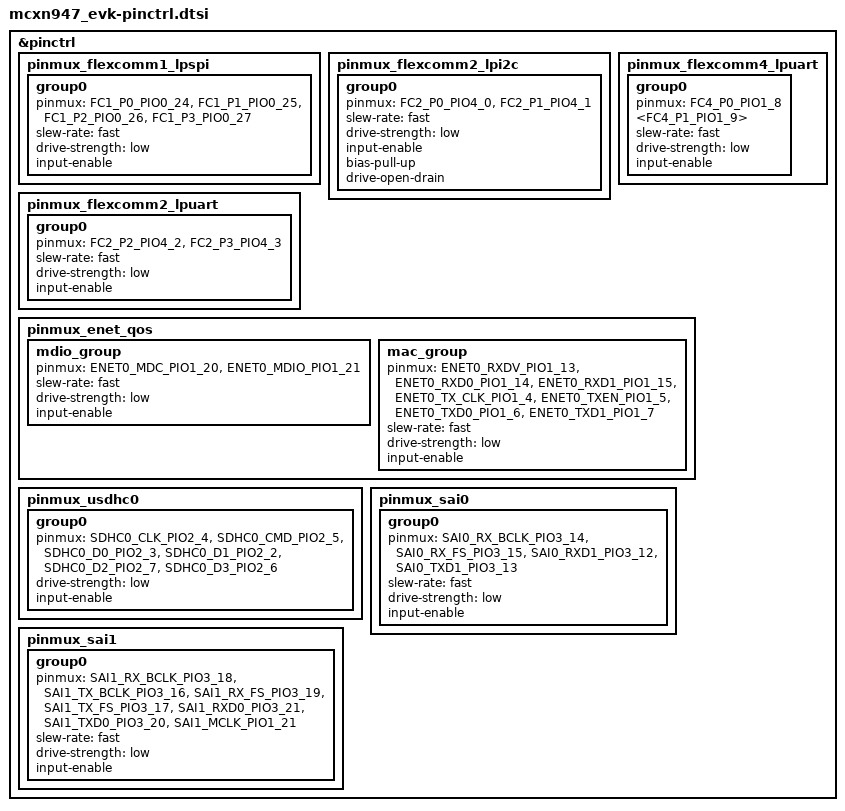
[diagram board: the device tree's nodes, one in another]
/*
 * Copyright 2024 Open Pixel Systems
 * SPDX-License-Identifier: Apache-2.0
 */

#include <nxp/mcx/MCXN947VDF-pinctrl.h>

&pinctrl {
	pinmux_flexcomm1_lpspi: pinmux_flexcomm1_lpspi {
		group0 {
			pinmux = <FC1_P0_PIO0_24>,
				<FC1_P1_PIO0_25>,
				<FC1_P2_PIO0_26>,
				<FC1_P3_PIO0_27>;
			slew-rate = "fast";
			drive-strength = "low";
			input-enable;
		};
	};

	pinmux_flexcomm2_lpi2c: pinmux_flexcomm2_lpi2c {
		group0 {
			pinmux = <FC2_P0_PIO4_0>,
				<FC2_P1_PIO4_1>;
			slew-rate = "fast";
			drive-strength = "low";
			input-enable;
			bias-pull-up;
			drive-open-drain;
		};
	};

	pinmux_flexcomm2_lpuart: pinmux_flexcomm2_lpuart {
		group0 {
			pinmux = <FC2_P2_PIO4_2>,
				<FC2_P3_PIO4_3>;
			slew-rate = "fast";
			drive-strength = "low";
			input-enable;
		};
	};

	pinmux_flexcomm4_lpuart: pinmux_flexcomm4_lpuart {
		group0 {
			pinmux = <FC4_P0_PIO1_8>;
				<FC4_P1_PIO1_9>;
			slew-rate = "fast";
			drive-strength = "low";
			input-enable;
		};
	};

	pinmux_enet_qos: pinmux_enet_qos {
		mdio_group {
			pinmux = <ENET0_MDC_PIO1_20>,
				<ENET0_MDIO_PIO1_21>;
			slew-rate = "fast";
			drive-strength = "low";
			input-enable;
		};
		mac_group {
			pinmux = <ENET0_RXDV_PIO1_13>,
				<ENET0_RXD0_PIO1_14>,
				<ENET0_RXD1_PIO1_15>,
				<ENET0_TX_CLK_PIO1_4>,
				<ENET0_TXEN_PIO1_5>,
				<ENET0_TXD0_PIO1_6>,
				<ENET0_TXD1_PIO1_7>;
			slew-rate = "fast";
			drive-strength = "low";
			input-enable;
		};
	};

	pinmux_usdhc0: pinmux_usdhc0{
		group0 {
			pinmux = <SDHC0_CLK_PIO2_4>,
				<SDHC0_CMD_PIO2_5>,
				<SDHC0_D0_PIO2_3>,
				<SDHC0_D1_PIO2_2>,
				<SDHC0_D2_PIO2_7>,
				<SDHC0_D3_PIO2_6>,
			slew-rate = "fast";
			drive-strength = "low";
			input-enable;
		};
	};

	pinmux_sai0: pinmux_sai0 {
		group0 {
			pinmux = <SAI0_RX_BCLK_PIO3_14>,
				<SAI0_RX_FS_PIO3_15>,
				<SAI0_RXD1_PIO3_12>.
				<SAI0_TXD1_PIO3_13>;
			slew-rate = "fast";
			drive-strength = "low";
			input-enable;
		};
	};

	pinmux_sai1: pinmux_sai1 {
		group0 {
			pinmux = <SAI1_RX_BCLK_PIO3_18>,
				<SAI1_TX_BCLK_PIO3_16>,
				<SAI1_RX_FS_PIO3_19>,
				<SAI1_TX_FS_PIO3_17>,
				<SAI1_RXD0_PIO3_21>,
				<SAI1_TXD0_PIO3_20>,
				<SAI1_MCLK_PIO1_21>;
			slew-rate = "fast";
			drive-strength = "low";
			input-enable;
		};
	};
};
